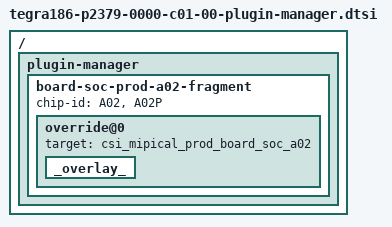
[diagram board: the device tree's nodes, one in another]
/*
 * tegra186-p2379-0000-c01-00-plugin-manager.dtsi: plugin mngr for 2379 platform
 *
 * Copyright (c) 2015-2016, NVIDIA CORPORATION.  All rights reserved.
 *
 * This program is free software; you can redistribute it and/or modify
 * it under the terms of the GNU General Public License as published by
 * the Free Software Foundation; version 2 of the License.
 *
 * This program is distributed in the hope that it will be useful, but WITHOUT
 * ANY WARRANTY; without even the implied warranty of MERCHANTABILITY or
 * FITNESS FOR A PARTICULAR PURPOSE.  See the GNU General Public License for
 * more details.
 */

#include "tegra186-soc-prod-plugin-manager.dtsi"

/ {
	plugin-manager {
		board-soc-prod-a02-fragment {
			chip-id = "A02", "A02P";
			override@0 {
				target = <&csi_mipical_prod_board_soc_a02>;
				_overlay_ {
					status = "okay";
				};
			};
		};
	};
};

